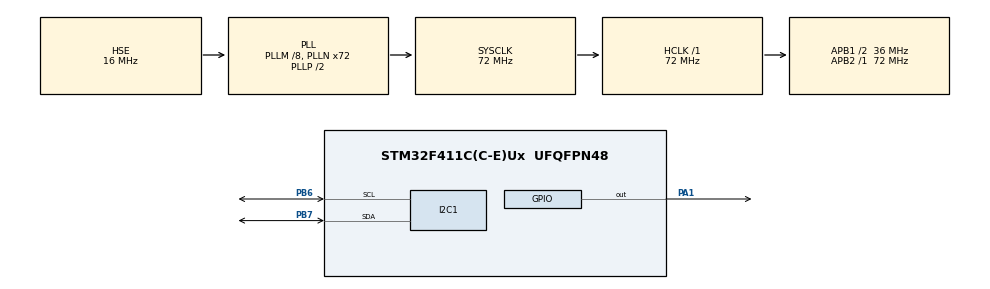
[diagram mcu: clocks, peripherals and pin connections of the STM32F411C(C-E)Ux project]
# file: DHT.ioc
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Mcu.Family=STM32F4
Mcu.Name=STM32F411C(C-E)Ux
Mcu.Package=UFQFPN48
NVIC.PriorityGroup=NVIC_PRIORITYGROUP_4
PA1.Signal=GPIO_Output
PA13.Mode=Serial_Wire
PA13.Signal=SYS_JTMS-SWDIO
PA14.Mode=Serial_Wire
PA14.Signal=SYS_JTCK-SWCLK
PB6.Mode=I2C
PB6.Signal=I2C1_SCL
PB7.Mode=I2C
PB7.Signal=I2C1_SDA
PH0\ -\ OSC_IN.Mode=HSE-External-Oscillator
PH0\ -\ OSC_IN.Signal=RCC_OSC_IN
PH1\ -\ OSC_OUT.Mode=HSE-External-Oscillator
PH1\ -\ OSC_OUT.Signal=RCC_OSC_OUT
ProjectManager.HeapSize=0x200
ProjectManager.StackSize=0x400
ProjectManager.TargetToolchain=STM32CubeIDE
RCC.48MHZClocksFreq_Value=36000000
RCC.AHBFreq_Value=72000000
RCC.APB1CLKDivider=RCC_HCLK_DIV2
RCC.APB1Freq_Value=36000000
RCC.APB1TimFreq_Value=72000000
RCC.APB2Freq_Value=72000000
RCC.APB2TimFreq_Value=72000000
RCC.CortexFreq_Value=72000000
RCC.HCLKFreq_Value=72000000
RCC.HSE_VALUE=16000000
RCC.HSI_VALUE=16000000
RCC.LSE_VALUE=32768
RCC.PLLM=8
RCC.PLLN=72
RCC.PLLSourceVirtual=RCC_PLLSOURCE_HSE
RCC.SYSCLKFreq_VALUE=72000000
RCC.SYSCLKSource=RCC_SYSCLKSOURCE_PLLCLK
RCC.VCOOutputFreq_Value=144000000
TIM1.Period=0xffff-1
TIM1.Prescaler=72-1
VP_TIM1_VS_ClockSourceINT.Mode=Internal
board=custom

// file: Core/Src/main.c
/* USER CODE BEGIN Header */
/**
  ******************************************************************************
  * @file           : main.c
  * @brief          : Main program body
  ******************************************************************************
  * @attention
  *
  * Copyright (c) 2021 STMicroelectronics.
  * All rights reserved.
  *
  * This software is licensed under terms that can be found in the LICENSE file
  * in the root directory of this software component.
  * If no LICENSE file comes with this software, it is provided AS-IS.
  *
  ******************************************************************************
  */
/* USER CODE END Header */
#include "main.h"

/* USER CODE BEGIN Includes */
#include "stdio.h"

/* USER CODE END Includes */

/* USER CODE BEGIN PD */
#define SLAVE_ADDRESS_LCD 0x4E

/* USER CODE END PD */

I2C_HandleTypeDef hi2c1;

TIM_HandleTypeDef htim1;

void SystemClock_Config(void);
static void MX_GPIO_Init(void);
static void MX_I2C1_Init(void);
static void MX_TIM1_Init(void);

/* USER CODE BEGIN 0 */

/*************************LCD Function*************************/

void lcd_send_cmd (char cmd)
{
  char data_u, data_l;
	uint8_t data_t[4];
	data_u = (cmd&0xf0);
	data_l = ((cmd<<4)&0xf0);
	data_t[0] = data_u|0x0C;  //en=1, rs=0
	data_t[1] = data_u|0x08;  //en=0, rs=0
	data_t[2] = data_l|0x0C;  //en=1, rs=0
	data_t[3] = data_l|0x08;  //en=0, rs=0
	HAL_I2C_Master_Transmit (&hi2c1, SLAVE_ADDRESS_LCD,(uint8_t *) data_t, 4, 100);
}

void lcd_send_data (char data)
{
	char data_u, data_l;
	uint8_t data_t[4];
	data_u = (data&0xf0);
	data_l = ((data<<4)&0xf0);
	data_t[0] = data_u|0x0D;  //en=1, rs=0
	data_t[1] = data_u|0x09;  //en=0, rs=0
	data_t[2] = data_l|0x0D;  //en=1, rs=0
	data_t[3] = data_l|0x09;  //en=0, rs=0
	HAL_I2C_Master_Transmit (&hi2c1, SLAVE_ADDRESS_LCD,(uint8_t *) data_t, 4, 100);
}

void lcd_clear (void)
{
	lcd_send_cmd(0x01);
	HAL_Delay(10);
}

void lcd_put_cur(int row, int col)
{
    switch (row)
    {
        case 0:
            col |= 0x80;
            break;
        case 1:
            col |= 0xC0;
            break;
    }
    lcd_send_cmd (col);
}

void lcd_init (void)
{
	// 4 bit initialisation
	HAL_Delay(50);  // wait for >40ms
	lcd_send_cmd (0x30);
	HAL_Delay(5);  // wait for >4.1ms
	lcd_send_cmd (0x30);
	HAL_Delay(1);  // wait for >100us
	lcd_send_cmd (0x30);
	HAL_Delay(10);
	lcd_send_cmd (0x20);  // 4bit mode
	HAL_Delay(10);

  // dislay initialisation
	lcd_send_cmd (0x28); // Function set --> DL=0 (4 bit mode), N = 1 (2 line display) F = 0 (5x8 characters)
	HAL_Delay(1);
	lcd_send_cmd (0x08); //Display on/off control --> D=0,C=0, B=0  ---> display off
	HAL_Delay(1);
	lcd_send_cmd (0x01);  // clear display
	HAL_Delay(1);
	HAL_Delay(1);
	lcd_send_cmd (0x06); //Entry mode set --> I/D = 1 (increment cursor) & S = 0 (no shift)
	HAL_Delay(1);
	lcd_send_cmd (0x0C); //Display on/off control --> D = 1, C and B = 0. (Cursor and blink, last two bits)
}

void lcd_send_string (char *str)
{
	while (*str) lcd_send_data (*str++);
}

/******************************************************/

void delay (uint16_t time)
{
	__HAL_TIM_SET_COUNTER(&htim1,0);  // set the counter value a 0
	while (__HAL_TIM_GET_COUNTER(&htim1) < time);  // wait for the counter to reach the us input in the parameter
}

void Display_Temp (float Temp)
{
	char str[20] = {0};
	lcd_put_cur(0, 0);

	sprintf (str, "Temp: %.2f ", Temp);
	lcd_send_string(str);
	lcd_send_string("C");
}

void Display_Rh (float Rh)
{
	char str[20] = {0};
	lcd_put_cur(1, 0);

	sprintf (str, "Rh: %.2f ", Rh);
	lcd_send_string(str);
	lcd_send_data('%');
}

uint8_t Rh_byte1, Rh_byte2, Temp_byte1, Temp_byte2;
uint16_t SUM, RH, TEMP;

float Temperature = 0;
float Humidity = 0;
uint8_t Presence = 0;

void Set_Pin_Output (GPIO_TypeDef *GPIOx, uint16_t GPIO_Pin)
{
	GPIO_InitTypeDef GPIO_InitStruct = {0};
	GPIO_InitStruct.Pin = GPIO_Pin;
	GPIO_InitStruct.Mode = GPIO_MODE_OUTPUT_PP;
	GPIO_InitStruct.Speed = GPIO_SPEED_FREQ_LOW;
	HAL_GPIO_Init(GPIOx, &GPIO_InitStruct);
}

void Set_Pin_Input (GPIO_TypeDef *GPIOx, uint16_t GPIO_Pin)
{
	GPIO_InitTypeDef GPIO_InitStruct = {0};
	GPIO_InitStruct.Pin = GPIO_Pin;
	GPIO_InitStruct.Mode = GPIO_MODE_INPUT;
	GPIO_InitStruct.Pull = GPIO_PULLUP;
	HAL_GPIO_Init(GPIOx, &GPIO_InitStruct);
}

/************************* DHT11 FUNCTIONS *****************************/

#define DHT11_PORT GPIOA
#define DHT11_PIN GPIO_PIN_1

void DHT11_Start (void)
{
	HAL_GPIO_WritePin(DHT11_PORT, DHT11_PIN, 1);     //Initialize with Data pin HIGH
	HAL_Delay(300);
	Set_Pin_Output (DHT11_PORT, DHT11_PIN);  // set the pin as output
	HAL_GPIO_WritePin (DHT11_PORT, DHT11_PIN, 0);   // pull the pin low
	delay(18000);   // wait for 18ms
    HAL_GPIO_WritePin (DHT11_PORT, DHT11_PIN, 1);   // pull the pin high
    delay(30);   // wait for 30us
	Set_Pin_Input(DHT11_PORT, DHT11_PIN);    // set as input
}

uint8_t DHT11_Check_Response (void)
{
	uint8_t Response = 0;
	delay(40);
	if (!(HAL_GPIO_ReadPin (DHT11_PORT, DHT11_PIN)))
	{
		delay(80);
		if ((HAL_GPIO_ReadPin (DHT11_PORT, DHT11_PIN))) Response = 1;
		else Response = -1;
	}
	while ((HAL_GPIO_ReadPin (DHT11_PORT, DHT11_PIN)));   // wait for the pin to go low

	return Response;
}

uint8_t DHT11_Read (void)
{
	uint8_t i,value;
	for (i=0;i<8;i++)
	{
		while (!(HAL_GPIO_ReadPin (DHT11_PORT, DHT11_PIN)));   // wait for the pin to go high
		delay(40);   // wait for 40 us
		if (!(HAL_GPIO_ReadPin (DHT11_PORT, DHT11_PIN)))   // if the pin is low
		{
			value&= ~(1<<(7-i));   // write 0
		}
		else value|= (1<<(7-i));  // if the pin is high, write 1
		while ((HAL_GPIO_ReadPin (DHT11_PORT, DHT11_PIN)));  // wait for the pin to go low
	}
	return i;
}

/* USER CODE END 0 */

int main(void)
{

  /* MCU Configuration--------------------------------------------------------*/

  /* Reset of all peripherals, Initializes the Flash interface and the Systick. */
  HAL_Init();

  /* Configure the system clock */
  SystemClock_Config();

  /* Initialize all configured peripherals */
  MX_GPIO_Init();
  MX_I2C1_Init();
  MX_TIM1_Init();
  /* USER CODE BEGIN 2 */

  HAL_TIM_Base_Start(&htim1);

  lcd_init();
  lcd_send_string("Nhom 2");
  HAL_Delay(2000);
  lcd_clear();

  /* USER CODE END 2 */

  /* Infinite loop */
  while (1)
  {

    /* USER CODE BEGIN 3 */

	  Display_Temp(Temperature);
	  Display_Rh(Humidity);

	  DHT11_Start();
	  Presence = DHT11_Check_Response();
	  Rh_byte1 = DHT11_Read();
	  Rh_byte2 = DHT11_Read();
	  Temp_byte1 = DHT11_Read();
	  Temp_byte2 = DHT11_Read();
	  SUM = DHT11_Read();

	  TEMP = Temp_byte1;
	  RH = Rh_byte1;

	  Temperature = (float) TEMP;
	  Humidity = (float) RH;

	  HAL_Delay(1000);

  }
  /* USER CODE END 3 */
}

void SystemClock_Config(void)
{
  RCC_OscInitTypeDef RCC_OscInitStruct = {0};
  RCC_ClkInitTypeDef RCC_ClkInitStruct = {0};

  /** Configure the main internal regulator output voltage
  */
  __HAL_RCC_PWR_CLK_ENABLE();
  __HAL_PWR_VOLTAGESCALING_CONFIG(PWR_REGULATOR_VOLTAGE_SCALE1);
  /** Initializes the RCC Oscillators according to the specified parameters
  * in the RCC_OscInitTypeDef structure.
  */
  RCC_OscInitStruct.OscillatorType = RCC_OSCILLATORTYPE_HSE;
  RCC_OscInitStruct.HSEState = RCC_HSE_ON;
  RCC_OscInitStruct.PLL.PLLState = RCC_PLL_ON;
  RCC_OscInitStruct.PLL.PLLSource = RCC_PLLSOURCE_HSE;
  RCC_OscInitStruct.PLL.PLLM = 8;
  RCC_OscInitStruct.PLL.PLLN = 72;
  RCC_OscInitStruct.PLL.PLLP = RCC_PLLP_DIV2;
  RCC_OscInitStruct.PLL.PLLQ = 4;
  if (HAL_RCC_OscConfig(&RCC_OscInitStruct) != HAL_OK)
  {
    Error_Handler();
  }
  /** Initializes the CPU, AHB and APB buses clocks
  */
  RCC_ClkInitStruct.ClockType = RCC_CLOCKTYPE_HCLK|RCC_CLOCKTYPE_SYSCLK
                              |RCC_CLOCKTYPE_PCLK1|RCC_CLOCKTYPE_PCLK2;
  RCC_ClkInitStruct.SYSCLKSource = RCC_SYSCLKSOURCE_PLLCLK;
  RCC_ClkInitStruct.AHBCLKDivider = RCC_SYSCLK_DIV1;
  RCC_ClkInitStruct.APB1CLKDivider = RCC_HCLK_DIV2;
  RCC_ClkInitStruct.APB2CLKDivider = RCC_HCLK_DIV1;

  if (HAL_RCC_ClockConfig(&RCC_ClkInitStruct, FLASH_LATENCY_2) != HAL_OK)
  {
    Error_Handler();
  }
}

static void MX_I2C1_Init(void)
{

  hi2c1.Instance = I2C1;
  hi2c1.Init.ClockSpeed = 100000;
  hi2c1.Init.DutyCycle = I2C_DUTYCYCLE_2;
  hi2c1.Init.OwnAddress1 = 0;
  hi2c1.Init.AddressingMode = I2C_ADDRESSINGMODE_7BIT;
  hi2c1.Init.DualAddressMode = I2C_DUALADDRESS_DISABLE;
  hi2c1.Init.OwnAddress2 = 0;
  hi2c1.Init.GeneralCallMode = I2C_GENERALCALL_DISABLE;
  hi2c1.Init.NoStretchMode = I2C_NOSTRETCH_DISABLE;
  if (HAL_I2C_Init(&hi2c1) != HAL_OK)
  {
    Error_Handler();
  }

}

static void MX_TIM1_Init(void)
{

  TIM_ClockConfigTypeDef sClockSourceConfig = {0};
  TIM_MasterConfigTypeDef sMasterConfig = {0};

  htim1.Instance = TIM1;
  htim1.Init.Prescaler = 72-1;
  htim1.Init.CounterMode = TIM_COUNTERMODE_UP;
  htim1.Init.Period = 0xffff-1;
  htim1.Init.ClockDivision = TIM_CLOCKDIVISION_DIV1;
  htim1.Init.RepetitionCounter = 0;
  htim1.Init.AutoReloadPreload = TIM_AUTORELOAD_PRELOAD_DISABLE;
  if (HAL_TIM_Base_Init(&htim1) != HAL_OK)
  {
    Error_Handler();
  }
  sClockSourceConfig.ClockSource = TIM_CLOCKSOURCE_INTERNAL;
  if (HAL_TIM_ConfigClockSource(&htim1, &sClockSourceConfig) != HAL_OK)
  {
    Error_Handler();
  }
  sMasterConfig.MasterOutputTrigger = TIM_TRGO_RESET;
  sMasterConfig.MasterSlaveMode = TIM_MASTERSLAVEMODE_DISABLE;
  if (HAL_TIMEx_MasterConfigSynchronization(&htim1, &sMasterConfig) != HAL_OK)
  {
    Error_Handler();
  }

}

static void MX_GPIO_Init(void)
{
  GPIO_InitTypeDef GPIO_InitStruct = {0};

  /* GPIO Ports Clock Enable */
  __HAL_RCC_GPIOH_CLK_ENABLE();
  __HAL_RCC_GPIOA_CLK_ENABLE();
  __HAL_RCC_GPIOB_CLK_ENABLE();

  /*Configure GPIO pin Output Level */
  HAL_GPIO_WritePin(GPIOA, GPIO_PIN_1, 1);

  /*Configure GPIO pin : PA1 */
  GPIO_InitStruct.Pin = GPIO_PIN_1;
  GPIO_InitStruct.Mode = GPIO_MODE_OUTPUT_PP;
  GPIO_InitStruct.Pull = GPIO_NOPULL;
  GPIO_InitStruct.Speed = GPIO_SPEED_FREQ_LOW;
  HAL_GPIO_Init(GPIOA, &GPIO_InitStruct);

}

void Error_Handler(void)
{
  __disable_irq();
  while (1)
  {
  }
}
